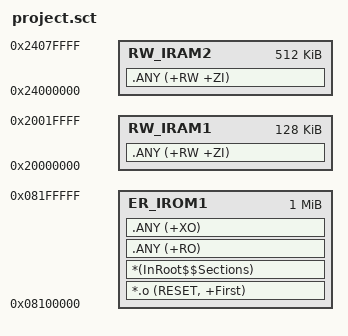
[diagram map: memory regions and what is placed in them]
; *************************************************************
; *** Scatter-Loading Description File generated by uVision ***
; *************************************************************

LR_IROM1 0x08100000 0x00100000  {    ; load region: app in Bank 2, 1MB
  ER_IROM1 0x08100000 0x00100000  {  ; execution region
   *.o (RESET, +First)
   *(InRoot$$Sections)
   .ANY (+RO)
   .ANY (+XO)
  }
  RW_IRAM1 0x20000000 0x00020000  {  ; RW data
   .ANY (+RW +ZI)
  }
  RW_IRAM2 0x24000000 0x00080000  {
   .ANY (+RW +ZI)
  }
}
